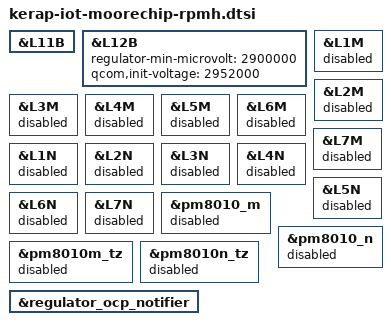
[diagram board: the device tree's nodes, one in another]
&L11B {
	/delete-property/ regulator-always-on;
};

&L12B {
	regulator-min-microvolt = <2900000>;
	qcom,init-voltage = <2952000>;
};

&L1M { status = "disabled"; };
&L2M { status = "disabled"; };
&L3M { status = "disabled"; };
&L4M { status = "disabled"; };
&L5M { status = "disabled"; };
&L6M { status = "disabled"; };
&L7M { status = "disabled"; };
&L1N { status = "disabled"; };
&L2N { status = "disabled"; };
&L3N { status = "disabled"; };
&L4N { status = "disabled"; };
&L5N { status = "disabled"; };
&L6N { status = "disabled"; };
&L7N { status = "disabled"; };

&pm8010_m { status = "disabled"; };
&pm8010_n { status = "disabled"; };
&pm8010m_tz { status = "disabled"; };
&pm8010n_tz { status = "disabled"; };

&regulator_ocp_notifier {
	/delete-property/ periph-c40-supply;
	/delete-property/ periph-c41-supply;
	/delete-property/ periph-c42-supply;
	/delete-property/ periph-c43-supply;
	/delete-property/ periph-c44-supply;
	/delete-property/ periph-c45-supply;
	/delete-property/ periph-c46-supply;
	/delete-property/ periph-d40-supply;
	/delete-property/ periph-d41-supply;
	/delete-property/ periph-d42-supply;
	/delete-property/ periph-d43-supply;
	/delete-property/ periph-d44-supply;
	/delete-property/ periph-d45-supply;
	/delete-property/ periph-d46-supply;
};
